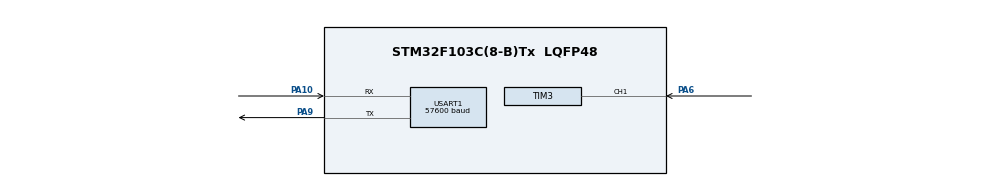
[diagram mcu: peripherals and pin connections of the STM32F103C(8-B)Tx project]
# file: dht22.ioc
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Dma.Request0=USART1_TX
Dma.USART1_TX.0.Direction=DMA_MEMORY_TO_PERIPH
Dma.USART1_TX.0.Instance=DMA1_Channel4
Dma.USART1_TX.0.MemDataAlignment=DMA_MDATAALIGN_BYTE
Dma.USART1_TX.0.MemInc=DMA_MINC_ENABLE
Dma.USART1_TX.0.Mode=DMA_NORMAL
Dma.USART1_TX.0.PeriphDataAlignment=DMA_PDATAALIGN_BYTE
Dma.USART1_TX.0.PeriphInc=DMA_PINC_DISABLE
Dma.USART1_TX.0.Priority=DMA_PRIORITY_LOW
Mcu.Family=STM32F1
Mcu.Name=STM32F103C(8-B)Tx
Mcu.Package=LQFP48
NVIC.DMA1_Channel4_IRQn=true\:0\:0\:false\:false\:true\:false
NVIC.PriorityGroup=NVIC_PRIORITYGROUP_4
NVIC.TIM3_IRQn=true\:0\:0\:false\:false\:true\:true
NVIC.USART1_IRQn=true\:0\:0\:false\:false\:true\:true
PA10.Mode=Asynchronous
PA10.Signal=USART1_RX
PA13.Mode=Serial_Wire
PA13.Signal=SYS_JTMS-SWDIO
PA14.Mode=Serial_Wire
PA14.Signal=SYS_JTCK-SWCLK
PA6.Signal=S_TIM3_CH1
PA9.Mode=Asynchronous
PA9.Signal=USART1_TX
ProjectManager.HeapSize=0x00
ProjectManager.StackSize=0x400
ProjectManager.TargetToolchain=Makefile
RCC.AHBFreq_Value=8000000
RCC.APB1Freq_Value=8000000
RCC.APB1TimFreq_Value=8000000
RCC.APB2Freq_Value=8000000
RCC.APB2TimFreq_Value=8000000
RCC.HCLKFreq_Value=8000000
SH.S_TIM3_CH1.0=TIM3_CH1,Input_Capture1_from_TI1
TIM3.Channel-Input_Capture1_from_TI1=TIM_CHANNEL_1
TIM3.ICPolarity_CH1=TIM_INPUTCHANNELPOLARITY_FALLING
TIM3.Period=65535
TIM3.Prescaler=7
USART1.BaudRate=57600
USART1.VirtualMode=VM_ASYNC
board=dht22

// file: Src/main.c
/**
 ******************************************************************************
 * File Name          : main.c
 * Description        : Main program body
 ******************************************************************************
 ** This notice applies to any and all portions of this file
 * that are not between comment pairs USER CODE BEGIN and
 * USER CODE END. Other portions of this file, whether
 * inserted by the user or by software development tools
 * are owned by their respective copyright owners.
 *
 * COPYRIGHT(c) 2018 STMicroelectronics
 *
 * Redistribution and use in source and binary forms, with or without
 *modification, are permitted provided that the following conditions are met:
 *   1. Redistributions of source code must retain the above copyright notice,
 *      this list of conditions and the following disclaimer.
 *   2. Redistributions in binary form must reproduce the above copyright
 *notice, this list of conditions and the following disclaimer in the
 *documentation and/or other materials provided with the distribution.
 *   3. Neither the name of STMicroelectronics nor the names of its contributors
 *      may be used to endorse or promote products derived from this software
 *      without specific prior written permission.
 *
 * THIS SOFTWARE IS PROVIDED BY THE COPYRIGHT HOLDERS AND CONTRIBUTORS "AS IS"
 * AND ANY EXPRESS OR IMPLIED WARRANTIES, INCLUDING, BUT NOT LIMITED TO, THE
 * IMPLIED WARRANTIES OF MERCHANTABILITY AND FITNESS FOR A PARTICULAR PURPOSE
 *ARE DISCLAIMED. IN NO EVENT SHALL THE COPYRIGHT HOLDER OR CONTRIBUTORS BE
 *LIABLE FOR ANY DIRECT, INDIRECT, INCIDENTAL, SPECIAL, EXEMPLARY, OR
 *CONSEQUENTIAL DAMAGES (INCLUDING, BUT NOT LIMITED TO, PROCUREMENT OF
 *SUBSTITUTE GOODS OR SERVICES; LOSS OF USE, DATA, OR PROFITS; OR BUSINESS
 *INTERRUPTION) HOWEVER CAUSED AND ON ANY THEORY OF LIABILITY, WHETHER IN
 *CONTRACT, STRICT LIABILITY, OR TORT (INCLUDING NEGLIGENCE OR OTHERWISE)
 *ARISING IN ANY WAY OUT OF THE USE OF THIS SOFTWARE, EVEN IF ADVISED OF THE
 *POSSIBILITY OF SUCH DAMAGE.
 *
 ******************************************************************************
 */

#include "main.h"
#include "stm32f1xx_hal.h"

/* USER CODE BEGIN Includes */
#include "example.h"
/* USER CODE END Includes */

TIM_HandleTypeDef htim3;

UART_HandleTypeDef huart1;
DMA_HandleTypeDef  hdma_usart1_tx;

/* USER CODE BEGIN PV */
/* Private variables ---------------------------------------------------------*/
/* USER CODE END PV */

void        SystemClock_Config(void);
static void MX_GPIO_Init(void);
static void MX_DMA_Init(void);
static void MX_TIM3_Init(void);
static void MX_USART1_UART_Init(void);

/* USER CODE BEGIN PFP */
/* Private function prototypes -----------------------------------------------*/

/* USER CODE END PFP */

int main(void) {

    /* MCU
     * Configuration----------------------------------------------------------*/

    /* Reset of all peripherals, Initializes the Flash interface and the
     * Systick. */
    HAL_Init();

    /* Configure the system clock */
    SystemClock_Config();

    /* Initialize all configured peripherals */
    MX_GPIO_Init();
    MX_DMA_Init();
    MX_TIM3_Init();
    MX_USART1_UART_Init();

    /* USER CODE BEGIN 2 */
    example();
    /* USER CODE END 2 */

    /* Infinite loop */
    while (1) {

    }
}

/** System Clock Configuration
 */
void SystemClock_Config(void) {

    RCC_OscInitTypeDef RCC_OscInitStruct;
    RCC_ClkInitTypeDef RCC_ClkInitStruct;

    /**Initializes the CPU, AHB and APB busses clocks
     */
    RCC_OscInitStruct.OscillatorType      = RCC_OSCILLATORTYPE_HSI;
    RCC_OscInitStruct.HSIState            = RCC_HSI_ON;
    RCC_OscInitStruct.HSICalibrationValue = 16;
    RCC_OscInitStruct.PLL.PLLState        = RCC_PLL_NONE;
    if (HAL_RCC_OscConfig(&RCC_OscInitStruct) != HAL_OK) {
        _Error_Handler(__FILE__, __LINE__);
    }

    /**Initializes the CPU, AHB and APB busses clocks
     */
    RCC_ClkInitStruct.ClockType = RCC_CLOCKTYPE_HCLK | RCC_CLOCKTYPE_SYSCLK |
                                  RCC_CLOCKTYPE_PCLK1 | RCC_CLOCKTYPE_PCLK2;
    RCC_ClkInitStruct.SYSCLKSource   = RCC_SYSCLKSOURCE_HSI;
    RCC_ClkInitStruct.AHBCLKDivider  = RCC_SYSCLK_DIV1;
    RCC_ClkInitStruct.APB1CLKDivider = RCC_HCLK_DIV1;
    RCC_ClkInitStruct.APB2CLKDivider = RCC_HCLK_DIV1;

    if (HAL_RCC_ClockConfig(&RCC_ClkInitStruct, FLASH_LATENCY_0) != HAL_OK) {
        _Error_Handler(__FILE__, __LINE__);
    }

    /**Configure the Systick interrupt time
     */
    HAL_SYSTICK_Config(HAL_RCC_GetHCLKFreq() / 1000);

    /**Configure the Systick
     */
    HAL_SYSTICK_CLKSourceConfig(SYSTICK_CLKSOURCE_HCLK);

    /* SysTick_IRQn interrupt configuration */
    HAL_NVIC_SetPriority(SysTick_IRQn, 0, 0);
}

/* TIM3 init function */
static void MX_TIM3_Init(void) {

    TIM_MasterConfigTypeDef sMasterConfig;
    TIM_IC_InitTypeDef      sConfigIC;

    htim3.Instance               = TIM3;
    htim3.Init.Prescaler         = 7;
    htim3.Init.CounterMode       = TIM_COUNTERMODE_UP;
    htim3.Init.Period            = 65535;
    htim3.Init.ClockDivision     = TIM_CLOCKDIVISION_DIV1;
    htim3.Init.AutoReloadPreload = TIM_AUTORELOAD_PRELOAD_DISABLE;
    if (HAL_TIM_IC_Init(&htim3) != HAL_OK) {
        _Error_Handler(__FILE__, __LINE__);
    }

    sMasterConfig.MasterOutputTrigger = TIM_TRGO_RESET;
    sMasterConfig.MasterSlaveMode     = TIM_MASTERSLAVEMODE_DISABLE;
    if (HAL_TIMEx_MasterConfigSynchronization(&htim3, &sMasterConfig) !=
        HAL_OK) {
        _Error_Handler(__FILE__, __LINE__);
    }

    sConfigIC.ICPolarity  = TIM_INPUTCHANNELPOLARITY_FALLING;
    sConfigIC.ICSelection = TIM_ICSELECTION_DIRECTTI;
    sConfigIC.ICPrescaler = TIM_ICPSC_DIV1;
    sConfigIC.ICFilter    = 0;
    if (HAL_TIM_IC_ConfigChannel(&htim3, &sConfigIC, TIM_CHANNEL_1) != HAL_OK) {
        _Error_Handler(__FILE__, __LINE__);
    }
}

/* USART1 init function */
static void MX_USART1_UART_Init(void) {

    huart1.Instance          = USART1;
    huart1.Init.BaudRate     = 57600;
    huart1.Init.WordLength   = UART_WORDLENGTH_8B;
    huart1.Init.StopBits     = UART_STOPBITS_1;
    huart1.Init.Parity       = UART_PARITY_NONE;
    huart1.Init.Mode         = UART_MODE_TX_RX;
    huart1.Init.HwFlowCtl    = UART_HWCONTROL_NONE;
    huart1.Init.OverSampling = UART_OVERSAMPLING_16;
    if (HAL_UART_Init(&huart1) != HAL_OK) {
        _Error_Handler(__FILE__, __LINE__);
    }
}

static void MX_DMA_Init(void) {
    /* DMA controller clock enable */
    __HAL_RCC_DMA1_CLK_ENABLE();

    /* DMA interrupt init */
    /* DMA1_Channel4_IRQn interrupt configuration */
    HAL_NVIC_SetPriority(DMA1_Channel4_IRQn, 0, 0);
    HAL_NVIC_EnableIRQ(DMA1_Channel4_IRQn);
}

/** Configure pins as
 * Analog
 * Input
 * Output
 * EVENT_OUT
 * EXTI
 */
static void MX_GPIO_Init(void) {

    /* GPIO Ports Clock Enable */
    __HAL_RCC_GPIOA_CLK_ENABLE();
}

void _Error_Handler(char* file, int line) {
    /* USER CODE BEGIN Error_Handler_Debug */
    /* User can add his own implementation to report the HAL error return state
     */
    while (1) {}
    /* USER CODE END Error_Handler_Debug */
}

#ifdef USE_FULL_ASSERT

/**
 * @brief Reports the name of the source file and the source line number
 * where the assert_param error has occurred.
 * @param file: pointer to the source file name
 * @param line: assert_param error line source number
 * @retval None
 */
void assert_failed(uint8_t* file, uint32_t line) {
    /* USER CODE BEGIN 6 */
    /* User can add his own implementation to report the file name and line
      number,
      ex: printf("Wrong parameters value: file %s on line %d\r\n", file, line)
      */
    /* USER CODE END 6 */
}

#endif

/************************ (C) COPYRIGHT STMicroelectronics *****END OF FILE****/
